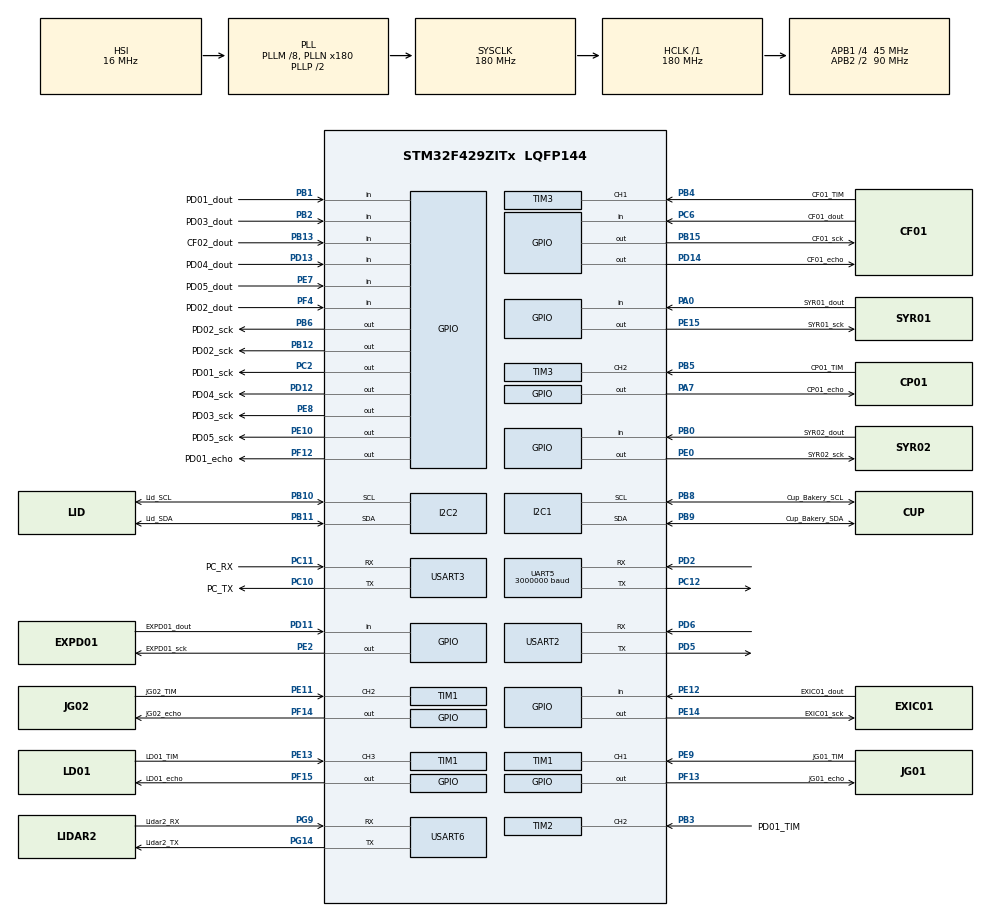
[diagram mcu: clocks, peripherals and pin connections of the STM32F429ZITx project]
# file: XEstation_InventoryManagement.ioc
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FREERTOS.Tasks01=defaultTask,24,128,StartDefaultTask,Default,NULL,Dynamic,NULL,NULL;Task_hx711_01,8,128,StartTask02,Default,NULL,Dynamic,NULL,NULL;Task_hx711_02,8,128,StartTask03,Default,NULL,Dynamic,NULL,NULL;Task_hx711_03,8,128,StartTask04,Default,NULL,Dynamic,NULL,NULL;Task_hx711_04,8,128,StartTask05,Default,NULL,Dynamic,NULL,NULL
FREERTOS.configUSE_NEWLIB_REENTRANT=1
Mcu.Family=STM32F4
Mcu.Name=STM32F429ZITx
Mcu.Package=LQFP144
NVIC.PriorityGroup=NVIC_PRIORITYGROUP_4
NVIC.TIM8_UP_TIM13_IRQn=true\:15\:0\:false\:false\:true\:false\:false\:true
NVIC.TimeBase=TIM8_UP_TIM13_IRQn
NVIC.TimeBaseIP=TIM13
NVIC.UART5_IRQn=true\:11\:0\:true\:false\:true\:true\:true\:true
NVIC.USART2_IRQn=true\:5\:0\:false\:false\:true\:true\:true\:true
NVIC.USART3_IRQn=true\:10\:0\:true\:false\:true\:true\:true\:true
PA0/WKUP.GPIO_Label=SYR01_dout
PA0/WKUP.Signal=GPIO_Input
PA7.GPIO_Label=CP01_echo
PA7.Signal=GPIO_Output
PB0.GPIO_Label=SYR02_dout
PB0.Signal=GPIO_Input
PB1.GPIO_Label=PD01_dout
PB1.Signal=GPIO_Input
PB10.GPIO_Label=Lid_SCL
PB10.Mode=I2C
PB10.Signal=I2C2_SCL
PB11.GPIO_Label=Lid_SDA
PB11.Mode=I2C
PB11.Signal=I2C2_SDA
PB12.GPIO_Label=PD02_sck
PB12.Signal=GPIO_Output
PB13.GPIO_Label=CF02_dout
PB13.Signal=GPIO_Input
PB15.GPIO_Label=CF01_sck
PB15.Signal=GPIO_Output
PB2/BOOT1.GPIO_Label=PD03_dout
PB2/BOOT1.Signal=GPIO_Input
PB3.GPIO_Label=PD01_TIM
PB3.Signal=S_TIM2_CH2
PB4.GPIO_Label=CF01_TIM
PB4.Signal=S_TIM3_CH1
PB5.GPIO_Label=CP01_TIM
PB5.Signal=S_TIM3_CH2
PB6.GPIO_Label=PD02_sck
PB6.Signal=GPIO_Output
PB8.GPIO_Label=Cup_Bakery_SCL
PB8.Mode=I2C
PB8.Signal=I2C1_SCL
PB9.GPIO_Label=Cup_Bakery_SDA
PB9.Mode=I2C
PB9.Signal=I2C1_SDA
PC10.GPIO_Label=PC_TX
PC10.Mode=Asynchronous
PC10.Signal=USART3_TX
PC11.GPIO_Label=PC_RX
PC11.Mode=Asynchronous
PC11.Signal=USART3_RX
PC12.GPIO_ModeDefaultPP=GPIO_MODE_AF_PP
PC12.GPIO_PuPd=GPIO_NOPULL
PC12.GPIO_Speed=GPIO_SPEED_FREQ_VERY_HIGH
PC12.Mode=Asynchronous
PC12.Signal=UART5_TX
PC2.GPIO_Label=PD01_sck
PC2.Signal=GPIO_Output
PC6.GPIO_Label=CF01_dout
PC6.Signal=GPIO_Input
PD11.GPIO_Label=EXPD01_dout
PD11.Signal=GPIO_Input
PD12.GPIO_Label=PD04_sck
PD12.Signal=GPIO_Output
PD13.GPIO_Label=PD04_dout
PD13.Signal=GPIO_Input
PD14.GPIO_Label=CF01_echo
PD14.Signal=GPIO_Output
PD2.GPIO_ModeDefaultPP=GPIO_MODE_AF_PP
PD2.GPIO_PuPd=GPIO_NOPULL
PD2.GPIO_Speed=GPIO_SPEED_FREQ_VERY_HIGH
PD2.Mode=Asynchronous
PD2.Signal=UART5_RX
PD5.Mode=Asynchronous
PD5.Signal=USART2_TX
PD6.Mode=Asynchronous
PD6.Signal=USART2_RX
PE0.GPIO_Label=SYR02_sck
PE0.Signal=GPIO_Output
PE10.GPIO_Label=PD05_sck
PE10.Signal=GPIO_Output
PE11.GPIO_Label=JG02_TIM
PE11.Signal=S_TIM1_CH2
PE12.GPIO_Label=EXIC01_dout
PE12.Signal=GPIO_Input
PE13.GPIO_Label=LD01_TIM
PE13.Signal=S_TIM1_CH3
PE14.GPIO_Label=EXIC01_sck
PE14.Signal=GPIO_Output
PE15.GPIO_Label=SYR01_sck
PE15.Signal=GPIO_Output
PE2.GPIO_Label=EXPD01_sck
PE2.Signal=GPIO_Output
PE7.GPIO_Label=PD05_dout
PE7.Signal=GPIO_Input
PE8.GPIO_Label=PD03_sck
PE8.Signal=GPIO_Output
PE9.GPIO_Label=JG01_TIM
PE9.Signal=S_TIM1_CH1
PF12.GPIO_Label=PD01_echo
PF12.Signal=GPIO_Output
PF13.GPIO_Label=JG01_echo
PF13.Signal=GPIO_Output
PF14.GPIO_Label=JG02_echo
PF14.Signal=GPIO_Output
PF15.GPIO_Label=LD01_echo
PF15.Signal=GPIO_Output
PF4.GPIO_Label=PD02_dout
PF4.Signal=GPIO_Input
PG14.GPIO_Label=Lidar2_TX
PG14.Mode=Asynchronous
PG14.Signal=USART6_TX
PG9.GPIO_Label=Lidar2_RX
PG9.Mode=Asynchronous
PG9.Signal=USART6_RX
ProjectManager.HeapSize=0x200
ProjectManager.StackSize=0x400
ProjectManager.TargetToolchain=STM32CubeIDE
RCC.48MHZClocksFreq_Value=90000000
RCC.AHBFreq_Value=180000000
RCC.APB1CLKDivider=RCC_HCLK_DIV4
RCC.APB1Freq_Value=45000000
RCC.APB1TimFreq_Value=90000000
RCC.APB2CLKDivider=RCC_HCLK_DIV2
RCC.APB2Freq_Value=90000000
RCC.APB2TimFreq_Value=180000000
RCC.CortexFreq_Value=180000000
RCC.HCLKFreq_Value=180000000
RCC.HSE_VALUE=25000000
RCC.HSI_VALUE=16000000
RCC.LSE_VALUE=32768
RCC.PLLM=8
RCC.PLLN=180
RCC.SYSCLKFreq_VALUE=180000000
RCC.SYSCLKSource=RCC_SYSCLKSOURCE_PLLCLK
RCC.VCOOutputFreq_Value=360000000
SH.S_TIM1_CH1.0=TIM1_CH1,Input_Capture1_from_TI1
SH.S_TIM1_CH2.0=TIM1_CH2,Input_Capture2_from_TI2
SH.S_TIM1_CH3.0=TIM1_CH3,Input_Capture3_from_TI3
SH.S_TIM2_CH2.0=TIM2_CH2,Input_Capture2_from_TI2
SH.S_TIM3_CH1.0=TIM3_CH1,TriggerSource_TI1ED
SH.S_TIM3_CH2.0=TIM3_CH2,Input_Capture2_from_TI2
TIM1.Channel-Input_Capture1_from_TI1=TIM_CHANNEL_1
TIM1.Channel-Input_Capture2_from_TI2=TIM_CHANNEL_2
TIM1.Channel-Input_Capture3_from_TI3=TIM_CHANNEL_3
TIM2.Channel-Input_Capture2_from_TI2=TIM_CHANNEL_2
TIM3.Channel-Input_Capture2_from_TI2=TIM_CHANNEL_2
TIM3.Prescaler=65535-1
UART5.BaudRate=3000000
UART5.OverSampling=UART_OVERSAMPLING_8
UART5.VirtualMode=Asynchronous
USART2.VirtualMode=VM_ASYNC
USART3.VirtualMode=VM_ASYNC
USART6.OverSampling=UART_OVERSAMPLING_8
USART6.VirtualMode=VM_ASYNC
VP_FREERTOS_VS_CMSIS_V2.Mode=CMSIS_V2
VP_SYS_VS_tim13.Mode=TIM13
VP_TIM1_VS_ClockSourceITR.Mode=TriggerSource_ITR0
VP_TIM2_VS_ClockSourceITR.Mode=TriggerSource_ITR0
board=custom

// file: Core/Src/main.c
/* USER CODE BEGIN Header */
/**
  ******************************************************************************
  * @file           : main.c
  * @brief          : Main program body
  ******************************************************************************
  * @attention
  *
  * <h2><center>&copy; Copyright (c) 2023 STMicroelectronics.
  * All rights reserved.</center></h2>
  *
  * This software component is licensed by ST under BSD 3-Clause license,
  * the "License"; You may not use this file except in compliance with the
  * License. You may obtain a copy of the License at:
  *                        opensource.org/licenses/BSD-3-Clause
  *
  ******************************************************************************
  */
/* USER CODE END Header */
#include "main.h"
#include "cmsis_os.h"

/* USER CODE BEGIN Includes */

#include "User_hx711.h"			// loadcell
#include "User_PC_serial.h"		// serial communication with PC
#include "User_TFminiS.h"		// TFminiS lidar sensor

/* USER CODE END Includes */

I2C_HandleTypeDef hi2c1;
I2C_HandleTypeDef hi2c2;

TIM_HandleTypeDef htim1;
TIM_HandleTypeDef htim2;
TIM_HandleTypeDef htim3;

UART_HandleTypeDef huart5;
UART_HandleTypeDef huart2;
UART_HandleTypeDef huart3;
UART_HandleTypeDef huart6;

/* Definitions for defaultTask */
osThreadId_t defaultTaskHandle;
const osThreadAttr_t defaultTask_attributes = {
  .name = "defaultTask",
  .stack_size = 128 * 4,
  .priority = (osPriority_t) osPriorityNormal,
};
/* Definitions for Task_hx711_01 */
osThreadId_t Task_hx711_01Handle;
const osThreadAttr_t Task_hx711_01_attributes = {
  .name = "Task_hx711_01",
  .stack_size = 128 * 4,
  .priority = (osPriority_t) osPriorityLow,
};
/* Definitions for Task_hx711_02 */
osThreadId_t Task_hx711_02Handle;
const osThreadAttr_t Task_hx711_02_attributes = {
  .name = "Task_hx711_02",
  .stack_size = 128 * 4,
  .priority = (osPriority_t) osPriorityLow,
};
/* Definitions for Task_hx711_03 */
osThreadId_t Task_hx711_03Handle;
const osThreadAttr_t Task_hx711_03_attributes = {
  .name = "Task_hx711_03",
  .stack_size = 128 * 4,
  .priority = (osPriority_t) osPriorityLow,
};
/* Definitions for Task_hx711_04 */
osThreadId_t Task_hx711_04Handle;
const osThreadAttr_t Task_hx711_04_attributes = {
  .name = "Task_hx711_04",
  .stack_size = 128 * 4,
  .priority = (osPriority_t) osPriorityLow,
};
/* USER CODE BEGIN PV */
//uint8_t UART5_rxBuffer[16] = {0};

uint8_t USART2_rxBuffer[16] = {0};
/* USER CODE END PV */

void SystemClock_Config(void);
static void MX_GPIO_Init(void);
static void MX_I2C1_Init(void);
static void MX_I2C2_Init(void);
static void MX_TIM1_Init(void);
static void MX_TIM2_Init(void);
static void MX_TIM3_Init(void);
static void MX_UART5_Init(void);
static void MX_USART3_UART_Init(void);
static void MX_USART6_UART_Init(void);
static void MX_USART2_UART_Init(void);
void StartDefaultTask(void *argument);
void StartTask02(void *argument);
void StartTask03(void *argument);
void StartTask04(void *argument);
void StartTask05(void *argument);

/* USER CODE BEGIN 0 */
int _write(int file, char *ptr, int len)
{
	if(HAL_UART_Transmit(&huart3, (uint8_t *)ptr, len, 10) == HAL_OK)
		return len;
	return -1;
}
/* USER CODE END 0 */

int main(void)
{

  /* MCU Configuration--------------------------------------------------------*/

  /* Reset of all peripherals, Initializes the Flash interface and the Systick. */
  HAL_Init();

  /* Configure the system clock */
  SystemClock_Config();

  /* Initialize all configured peripherals */
  MX_GPIO_Init();
  MX_I2C1_Init();
  MX_I2C2_Init();
  MX_TIM1_Init();
  MX_TIM2_Init();
  MX_TIM3_Init();
  MX_UART5_Init();
  MX_USART3_UART_Init();
  MX_USART6_UART_Init();
  MX_USART2_UART_Init();
  /* USER CODE BEGIN 2 */
  	TFminiS_setting();
//  	getDistance(0);
//  init_Lidar();
//  Lidar3dTest();
//  printf("start hx711 !!\n");
//  initHx711();

  /* USER CODE END 2 */

  /* Init scheduler */
  osKernelInitialize();

  /* Create the thread(s) */
  /* creation of defaultTask */
  defaultTaskHandle = osThreadNew(StartDefaultTask, NULL, &defaultTask_attributes);

  /* creation of Task_hx711_01 */
  Task_hx711_01Handle = osThreadNew(StartTask02, NULL, &Task_hx711_01_attributes);

  /* creation of Task_hx711_02 */
  Task_hx711_02Handle = osThreadNew(StartTask03, NULL, &Task_hx711_02_attributes);

  /* creation of Task_hx711_03 */
  Task_hx711_03Handle = osThreadNew(StartTask04, NULL, &Task_hx711_03_attributes);

  /* creation of Task_hx711_04 */
  Task_hx711_04Handle = osThreadNew(StartTask05, NULL, &Task_hx711_04_attributes);

  /* Start scheduler */
  osKernelStart();

  /* We should never get here as control is now taken by the scheduler */
  /* Infinite loop */
  while (1)
  {

    /* USER CODE BEGIN 3 */
//	  pcTest();
//	  runHx711(6);
//	  HAL_Delay(1000);
  }
  /* USER CODE END 3 */
}

void SystemClock_Config(void)
{
  RCC_OscInitTypeDef RCC_OscInitStruct = {0};
  RCC_ClkInitTypeDef RCC_ClkInitStruct = {0};

  /** Configure the main internal regulator output voltage
  */
  __HAL_RCC_PWR_CLK_ENABLE();
  __HAL_PWR_VOLTAGESCALING_CONFIG(PWR_REGULATOR_VOLTAGE_SCALE1);
  /** Initializes the RCC Oscillators according to the specified parameters
  * in the RCC_OscInitTypeDef structure.
  */
  RCC_OscInitStruct.OscillatorType = RCC_OSCILLATORTYPE_HSI;
  RCC_OscInitStruct.HSIState = RCC_HSI_ON;
  RCC_OscInitStruct.HSICalibrationValue = RCC_HSICALIBRATION_DEFAULT;
  RCC_OscInitStruct.PLL.PLLState = RCC_PLL_ON;
  RCC_OscInitStruct.PLL.PLLSource = RCC_PLLSOURCE_HSI;
  RCC_OscInitStruct.PLL.PLLM = 8;
  RCC_OscInitStruct.PLL.PLLN = 180;
  RCC_OscInitStruct.PLL.PLLP = RCC_PLLP_DIV2;
  RCC_OscInitStruct.PLL.PLLQ = 4;
  if (HAL_RCC_OscConfig(&RCC_OscInitStruct) != HAL_OK)
  {
    Error_Handler();
  }
  /** Activate the Over-Drive mode
  */
  if (HAL_PWREx_EnableOverDrive() != HAL_OK)
  {
    Error_Handler();
  }
  /** Initializes the CPU, AHB and APB buses clocks
  */
  RCC_ClkInitStruct.ClockType = RCC_CLOCKTYPE_HCLK|RCC_CLOCKTYPE_SYSCLK
                              |RCC_CLOCKTYPE_PCLK1|RCC_CLOCKTYPE_PCLK2;
  RCC_ClkInitStruct.SYSCLKSource = RCC_SYSCLKSOURCE_PLLCLK;
  RCC_ClkInitStruct.AHBCLKDivider = RCC_SYSCLK_DIV1;
  RCC_ClkInitStruct.APB1CLKDivider = RCC_HCLK_DIV4;
  RCC_ClkInitStruct.APB2CLKDivider = RCC_HCLK_DIV2;

  if (HAL_RCC_ClockConfig(&RCC_ClkInitStruct, FLASH_LATENCY_5) != HAL_OK)
  {
    Error_Handler();
  }
}

static void MX_I2C1_Init(void)
{

  hi2c1.Instance = I2C1;
  hi2c1.Init.ClockSpeed = 100000;
  hi2c1.Init.DutyCycle = I2C_DUTYCYCLE_2;
  hi2c1.Init.OwnAddress1 = 0;
  hi2c1.Init.AddressingMode = I2C_ADDRESSINGMODE_7BIT;
  hi2c1.Init.DualAddressMode = I2C_DUALADDRESS_DISABLE;
  hi2c1.Init.OwnAddress2 = 0;
  hi2c1.Init.GeneralCallMode = I2C_GENERALCALL_DISABLE;
  hi2c1.Init.NoStretchMode = I2C_NOSTRETCH_DISABLE;
  if (HAL_I2C_Init(&hi2c1) != HAL_OK)
  {
    Error_Handler();
  }
  /** Configure Analogue filter
  */
  if (HAL_I2CEx_ConfigAnalogFilter(&hi2c1, I2C_ANALOGFILTER_ENABLE) != HAL_OK)
  {
    Error_Handler();
  }
  /** Configure Digital filter
  */
  if (HAL_I2CEx_ConfigDigitalFilter(&hi2c1, 0) != HAL_OK)
  {
    Error_Handler();
  }

}

static void MX_I2C2_Init(void)
{

  hi2c2.Instance = I2C2;
  hi2c2.Init.ClockSpeed = 100000;
  hi2c2.Init.DutyCycle = I2C_DUTYCYCLE_2;
  hi2c2.Init.OwnAddress1 = 0;
  hi2c2.Init.AddressingMode = I2C_ADDRESSINGMODE_7BIT;
  hi2c2.Init.DualAddressMode = I2C_DUALADDRESS_DISABLE;
  hi2c2.Init.OwnAddress2 = 0;
  hi2c2.Init.GeneralCallMode = I2C_GENERALCALL_DISABLE;
  hi2c2.Init.NoStretchMode = I2C_NOSTRETCH_DISABLE;
  if (HAL_I2C_Init(&hi2c2) != HAL_OK)
  {
    Error_Handler();
  }
  /** Configure Analogue filter
  */
  if (HAL_I2CEx_ConfigAnalogFilter(&hi2c2, I2C_ANALOGFILTER_ENABLE) != HAL_OK)
  {
    Error_Handler();
  }
  /** Configure Digital filter
  */
  if (HAL_I2CEx_ConfigDigitalFilter(&hi2c2, 0) != HAL_OK)
  {
    Error_Handler();
  }

}

static void MX_TIM1_Init(void)
{

  TIM_SlaveConfigTypeDef sSlaveConfig = {0};
  TIM_MasterConfigTypeDef sMasterConfig = {0};
  TIM_IC_InitTypeDef sConfigIC = {0};

  htim1.Instance = TIM1;
  htim1.Init.Prescaler = 0;
  htim1.Init.CounterMode = TIM_COUNTERMODE_UP;
  htim1.Init.Period = 65535;
  htim1.Init.ClockDivision = TIM_CLOCKDIVISION_DIV1;
  htim1.Init.RepetitionCounter = 0;
  htim1.Init.AutoReloadPreload = TIM_AUTORELOAD_PRELOAD_DISABLE;
  if (HAL_TIM_Base_Init(&htim1) != HAL_OK)
  {
    Error_Handler();
  }
  if (HAL_TIM_IC_Init(&htim1) != HAL_OK)
  {
    Error_Handler();
  }
  sSlaveConfig.SlaveMode = TIM_SLAVEMODE_DISABLE;
  sSlaveConfig.InputTrigger = TIM_TS_ITR0;
  if (HAL_TIM_SlaveConfigSynchro(&htim1, &sSlaveConfig) != HAL_OK)
  {
    Error_Handler();
  }
  sMasterConfig.MasterOutputTrigger = TIM_TRGO_RESET;
  sMasterConfig.MasterSlaveMode = TIM_MASTERSLAVEMODE_DISABLE;
  if (HAL_TIMEx_MasterConfigSynchronization(&htim1, &sMasterConfig) != HAL_OK)
  {
    Error_Handler();
  }
  sConfigIC.ICPolarity = TIM_INPUTCHANNELPOLARITY_RISING;
  sConfigIC.ICSelection = TIM_ICSELECTION_DIRECTTI;
  sConfigIC.ICPrescaler = TIM_ICPSC_DIV1;
  sConfigIC.ICFilter = 0;
  if (HAL_TIM_IC_ConfigChannel(&htim1, &sConfigIC, TIM_CHANNEL_1) != HAL_OK)
  {
    Error_Handler();
  }
  if (HAL_TIM_IC_ConfigChannel(&htim1, &sConfigIC, TIM_CHANNEL_2) != HAL_OK)
  {
    Error_Handler();
  }
  if (HAL_TIM_IC_ConfigChannel(&htim1, &sConfigIC, TIM_CHANNEL_3) != HAL_OK)
  {
    Error_Handler();
  }

}

static void MX_TIM2_Init(void)
{

  TIM_SlaveConfigTypeDef sSlaveConfig = {0};
  TIM_MasterConfigTypeDef sMasterConfig = {0};
  TIM_IC_InitTypeDef sConfigIC = {0};

  htim2.Instance = TIM2;
  htim2.Init.Prescaler = 0;
  htim2.Init.CounterMode = TIM_COUNTERMODE_UP;
  htim2.Init.Period = 4294967295;
  htim2.Init.ClockDivision = TIM_CLOCKDIVISION_DIV1;
  htim2.Init.AutoReloadPreload = TIM_AUTORELOAD_PRELOAD_DISABLE;
  if (HAL_TIM_Base_Init(&htim2) != HAL_OK)
  {
    Error_Handler();
  }
  if (HAL_TIM_IC_Init(&htim2) != HAL_OK)
  {
    Error_Handler();
  }
  sSlaveConfig.SlaveMode = TIM_SLAVEMODE_DISABLE;
  sSlaveConfig.InputTrigger = TIM_TS_ITR0;
  if (HAL_TIM_SlaveConfigSynchro(&htim2, &sSlaveConfig) != HAL_OK)
  {
    Error_Handler();
  }
  sMasterConfig.MasterOutputTrigger = TIM_TRGO_RESET;
  sMasterConfig.MasterSlaveMode = TIM_MASTERSLAVEMODE_DISABLE;
  if (HAL_TIMEx_MasterConfigSynchronization(&htim2, &sMasterConfig) != HAL_OK)
  {
    Error_Handler();
  }
  sConfigIC.ICPolarity = TIM_INPUTCHANNELPOLARITY_RISING;
  sConfigIC.ICSelection = TIM_ICSELECTION_DIRECTTI;
  sConfigIC.ICPrescaler = TIM_ICPSC_DIV1;
  sConfigIC.ICFilter = 0;
  if (HAL_TIM_IC_ConfigChannel(&htim2, &sConfigIC, TIM_CHANNEL_2) != HAL_OK)
  {
    Error_Handler();
  }

}

static void MX_TIM3_Init(void)
{

  TIM_SlaveConfigTypeDef sSlaveConfig = {0};
  TIM_MasterConfigTypeDef sMasterConfig = {0};
  TIM_IC_InitTypeDef sConfigIC = {0};

  htim3.Instance = TIM3;
  htim3.Init.Prescaler = 65535-1;
  htim3.Init.CounterMode = TIM_COUNTERMODE_UP;
  htim3.Init.Period = 65535;
  htim3.Init.ClockDivision = TIM_CLOCKDIVISION_DIV1;
  htim3.Init.AutoReloadPreload = TIM_AUTORELOAD_PRELOAD_DISABLE;
  if (HAL_TIM_Base_Init(&htim3) != HAL_OK)
  {
    Error_Handler();
  }
  if (HAL_TIM_IC_Init(&htim3) != HAL_OK)
  {
    Error_Handler();
  }
  sSlaveConfig.SlaveMode = TIM_SLAVEMODE_DISABLE;
  sSlaveConfig.InputTrigger = TIM_TS_TI1F_ED;
  sSlaveConfig.TriggerFilter = 0;
  if (HAL_TIM_SlaveConfigSynchro(&htim3, &sSlaveConfig) != HAL_OK)
  {
    Error_Handler();
  }
  sMasterConfig.MasterOutputTrigger = TIM_TRGO_RESET;
  sMasterConfig.MasterSlaveMode = TIM_MASTERSLAVEMODE_DISABLE;
  if (HAL_TIMEx_MasterConfigSynchronization(&htim3, &sMasterConfig) != HAL_OK)
  {
    Error_Handler();
  }
  sConfigIC.ICPolarity = TIM_INPUTCHANNELPOLARITY_RISING;
  sConfigIC.ICSelection = TIM_ICSELECTION_DIRECTTI;
  sConfigIC.ICPrescaler = TIM_ICPSC_DIV1;
  sConfigIC.ICFilter = 0;
  if (HAL_TIM_IC_ConfigChannel(&htim3, &sConfigIC, TIM_CHANNEL_2) != HAL_OK)
  {
    Error_Handler();
  }

}

static void MX_UART5_Init(void)
{

  huart5.Instance = UART5;
  huart5.Init.BaudRate = 3000000;
  huart5.Init.WordLength = UART_WORDLENGTH_8B;
  huart5.Init.StopBits = UART_STOPBITS_1;
  huart5.Init.Parity = UART_PARITY_NONE;
  huart5.Init.Mode = UART_MODE_TX_RX;
  huart5.Init.HwFlowCtl = UART_HWCONTROL_NONE;
  huart5.Init.OverSampling = UART_OVERSAMPLING_8;
  if (HAL_UART_Init(&huart5) != HAL_OK)
  {
    Error_Handler();
  }

}

static void MX_USART2_UART_Init(void)
{

  huart2.Instance = USART2;
  huart2.Init.BaudRate = 115200;
  huart2.Init.WordLength = UART_WORDLENGTH_8B;
  huart2.Init.StopBits = UART_STOPBITS_1;
  huart2.Init.Parity = UART_PARITY_NONE;
  huart2.Init.Mode = UART_MODE_TX_RX;
  huart2.Init.HwFlowCtl = UART_HWCONTROL_NONE;
  huart2.Init.OverSampling = UART_OVERSAMPLING_16;
  if (HAL_UART_Init(&huart2) != HAL_OK)
  {
    Error_Handler();
  }

}

static void MX_USART3_UART_Init(void)
{

  huart3.Instance = USART3;
  huart3.Init.BaudRate = 115200;
  huart3.Init.WordLength = UART_WORDLENGTH_8B;
  huart3.Init.StopBits = UART_STOPBITS_1;
  huart3.Init.Parity = UART_PARITY_NONE;
  huart3.Init.Mode = UART_MODE_TX_RX;
  huart3.Init.HwFlowCtl = UART_HWCONTROL_NONE;
  huart3.Init.OverSampling = UART_OVERSAMPLING_16;
  if (HAL_UART_Init(&huart3) != HAL_OK)
  {
    Error_Handler();
  }

}

static void MX_USART6_UART_Init(void)
{

  huart6.Instance = USART6;
  huart6.Init.BaudRate = 115200;
  huart6.Init.WordLength = UART_WORDLENGTH_8B;
  huart6.Init.StopBits = UART_STOPBITS_1;
  huart6.Init.Parity = UART_PARITY_NONE;
  huart6.Init.Mode = UART_MODE_TX_RX;
  huart6.Init.HwFlowCtl = UART_HWCONTROL_NONE;
  huart6.Init.OverSampling = UART_OVERSAMPLING_8;
  if (HAL_UART_Init(&huart6) != HAL_OK)
  {
    Error_Handler();
  }

}

static void MX_GPIO_Init(void)
{
  GPIO_InitTypeDef GPIO_InitStruct = {0};

  /* GPIO Ports Clock Enable */
  __HAL_RCC_GPIOE_CLK_ENABLE();
  __HAL_RCC_GPIOF_CLK_ENABLE();
  __HAL_RCC_GPIOC_CLK_ENABLE();
  __HAL_RCC_GPIOA_CLK_ENABLE();
  __HAL_RCC_GPIOB_CLK_ENABLE();
  __HAL_RCC_GPIOD_CLK_ENABLE();
  __HAL_RCC_GPIOG_CLK_ENABLE();

  /*Configure GPIO pin Output Level */
  HAL_GPIO_WritePin(GPIOE, EXPD01_sck_Pin|PD03_sck_Pin|PD05_sck_Pin|EXIC01_sck_Pin
                          |SYR01_sck_Pin|SYR02_sck_Pin, GPIO_PIN_RESET);

  /*Configure GPIO pin Output Level */
  HAL_GPIO_WritePin(PD01_sck_GPIO_Port, PD01_sck_Pin, GPIO_PIN_RESET);

  /*Configure GPIO pin Output Level */
  HAL_GPIO_WritePin(CP01_echo_GPIO_Port, CP01_echo_Pin, GPIO_PIN_RESET);

  /*Configure GPIO pin Output Level */
  HAL_GPIO_WritePin(GPIOF, PD01_echo_Pin|JG01_echo_Pin|JG02_echo_Pin|LD01_echo_Pin, GPIO_PIN_RESET);

  /*Configure GPIO pin Output Level */
  HAL_GPIO_WritePin(GPIOB, PD02_sck_Pin|CF01_sck_Pin|PD02_sckB6_Pin, GPIO_PIN_RESET);

  /*Configure GPIO pin Output Level */
  HAL_GPIO_WritePin(GPIOD, PD04_sck_Pin|CF01_echo_Pin, GPIO_PIN_RESET);

  /*Configure GPIO pins : EXPD01_sck_Pin PD03_sck_Pin PD05_sck_Pin EXIC01_sck_Pin
                           SYR01_sck_Pin SYR02_sck_Pin */
  GPIO_InitStruct.Pin = EXPD01_sck_Pin|PD03_sck_Pin|PD05_sck_Pin|EXIC01_sck_Pin
                          |SYR01_sck_Pin|SYR02_sck_Pin;
  GPIO_InitStruct.Mode = GPIO_MODE_OUTPUT_PP;
  GPIO_InitStruct.Pull = GPIO_NOPULL;
  GPIO_InitStruct.Speed = GPIO_SPEED_FREQ_LOW;
  HAL_GPIO_Init(GPIOE, &GPIO_InitStruct);

  /*Configure GPIO pin : PD02_dout_Pin */
  GPIO_InitStruct.Pin = PD02_dout_Pin;
  GPIO_InitStruct.Mode = GPIO_MODE_INPUT;
  GPIO_InitStruct.Pull = GPIO_NOPULL;
  HAL_GPIO_Init(PD02_dout_GPIO_Port, &GPIO_InitStruct);

  /*Configure GPIO pin : PD01_sck_Pin */
  GPIO_InitStruct.Pin = PD01_sck_Pin;
  GPIO_InitStruct.Mode = GPIO_MODE_OUTPUT_PP;
  GPIO_InitStruct.Pull = GPIO_NOPULL;
  GPIO_InitStruct.Speed = GPIO_SPEED_FREQ_LOW;
  HAL_GPIO_Init(PD01_sck_GPIO_Port, &GPIO_InitStruct);

  /*Configure GPIO pin : SYR01_dout_Pin */
  GPIO_InitStruct.Pin = SYR01_dout_Pin;
  GPIO_InitStruct.Mode = GPIO_MODE_INPUT;
  GPIO_InitStruct.Pull = GPIO_NOPULL;
  HAL_GPIO_Init(SYR01_dout_GPIO_Port, &GPIO_InitStruct);

  /*Configure GPIO pin : CP01_echo_Pin */
  GPIO_InitStruct.Pin = CP01_echo_Pin;
  GPIO_InitStruct.Mode = GPIO_MODE_OUTPUT_PP;
  GPIO_InitStruct.Pull = GPIO_NOPULL;
  GPIO_InitStruct.Speed = GPIO_SPEED_FREQ_LOW;
  HAL_GPIO_Init(CP01_echo_GPIO_Port, &GPIO_InitStruct);

  /*Configure GPIO pins : SYR02_dout_Pin PD01_dout_Pin PD03_dout_Pin CF02_dout_Pin */
  GPIO_InitStruct.Pin = SYR02_dout_Pin|PD01_dout_Pin|PD03_dout_Pin|CF02_dout_Pin;
  GPIO_InitStruct.Mode = GPIO_MODE_INPUT;
  GPIO_InitStruct.Pull = GPIO_NOPULL;
  HAL_GPIO_Init(GPIOB, &GPIO_InitStruct);

  /*Configure GPIO pins : PD01_echo_Pin JG01_echo_Pin JG02_echo_Pin LD01_echo_Pin */
  GPIO_InitStruct.Pin = PD01_echo_Pin|JG01_echo_Pin|JG02_echo_Pin|LD01_echo_Pin;
  GPIO_InitStruct.Mode = GPIO_MODE_OUTPUT_PP;
  GPIO_InitStruct.Pull = GPIO_NOPULL;
  GPIO_InitStruct.Speed = GPIO_SPEED_FREQ_LOW;
  HAL_GPIO_Init(GPIOF, &GPIO_InitStruct);

  /*Configure GPIO pins : PD05_dout_Pin EXIC01_dout_Pin */
  GPIO_InitStruct.Pin = PD05_dout_Pin|EXIC01_dout_Pin;
  GPIO_InitStruct.Mode = GPIO_MODE_INPUT;
  GPIO_InitStruct.Pull = GPIO_NOPULL;
  HAL_GPIO_Init(GPIOE, &GPIO_InitStruct);

  /*Configure GPIO pins : PD02_sck_Pin CF01_sck_Pin PD02_sckB6_Pin */
  GPIO_InitStruct.Pin = PD02_sck_Pin|CF01_sck_Pin|PD02_sckB6_Pin;
  GPIO_InitStruct.Mode = GPIO_MODE_OUTPUT_PP;
  GPIO_InitStruct.Pull = GPIO_NOPULL;
  GPIO_InitStruct.Speed = GPIO_SPEED_FREQ_LOW;
  HAL_GPIO_Init(GPIOB, &GPIO_InitStruct);

  /*Configure GPIO pins : EXPD01_dout_Pin PD04_dout_Pin */
  GPIO_InitStruct.Pin = EXPD01_dout_Pin|PD04_dout_Pin;
  GPIO_InitStruct.Mode = GPIO_MODE_INPUT;
  GPIO_InitStruct.Pull = GPIO_NOPULL;
  HAL_GPIO_Init(GPIOD, &GPIO_InitStruct);

  /*Configure GPIO pins : PD04_sck_Pin CF01_echo_Pin */
  GPIO_InitStruct.Pin = PD04_sck_Pin|CF01_echo_Pin;
  GPIO_InitStruct.Mode = GPIO_MODE_OUTPUT_PP;
  GPIO_InitStruct.Pull = GPIO_NOPULL;
  GPIO_InitStruct.Speed = GPIO_SPEED_FREQ_LOW;
  HAL_GPIO_Init(GPIOD, &GPIO_InitStruct);

  /*Configure GPIO pin : CF01_dout_Pin */
  GPIO_InitStruct.Pin = CF01_dout_Pin;
  GPIO_InitStruct.Mode = GPIO_MODE_INPUT;
  GPIO_InitStruct.Pull = GPIO_NOPULL;
  HAL_GPIO_Init(CF01_dout_GPIO_Port, &GPIO_InitStruct);

}

void StartDefaultTask(void *argument)
{
  /* USER CODE BEGIN 5 */
  /* Infinite loop */
  for(;;)
  {
//	 printf("test01\n");
	 HAL_Delay(1000);
	 //	  runHx711(0);
    osDelay(1);
  }
  /* USER CODE END 5 */
}

void StartTask02(void *argument)
{
  /* USER CODE BEGIN StartTask02 */
  /* Infinite loop */
  for(;;)
  {
//	 printf("test02\n");
		 HAL_Delay(1005);

//	  runHx711(1);

    osDelay(1);
  }
  /* USER CODE END StartTask02 */
}

void StartTask03(void *argument)
{
  /* USER CODE BEGIN StartTask03 */
  /* Infinite loop */
  for(;;)
  {
//		 printf("test03\n");
			 HAL_Delay(1025);
    osDelay(1);
  }
  /* USER CODE END StartTask03 */
}

void StartTask04(void *argument)
{
  /* USER CODE BEGIN StartTask04 */
  /* Infinite loop */
  for(;;)
  {
//	  runHx711(2);
//		 printf("test04\n");
			 HAL_Delay(1055);
    osDelay(1);
  }
  /* USER CODE END StartTask04 */
}

void StartTask05(void *argument)
{
  /* USER CODE BEGIN StartTask05 */
  /* Infinite loop */
  for(;;)
  {
//	  runHx711(3);
	  runHx711(0);
    osDelay(1);
  }
  /* USER CODE END StartTask05 */
}

void HAL_TIM_PeriodElapsedCallback(TIM_HandleTypeDef *htim)
{
  if (htim->Instance == TIM13) {
    HAL_IncTick();
  }
}

void Error_Handler(void)
{
  __disable_irq();
  while (1)
  {
  }
}

/************************ (C) COPYRIGHT STMicroelectronics *****END OF FILE****/
